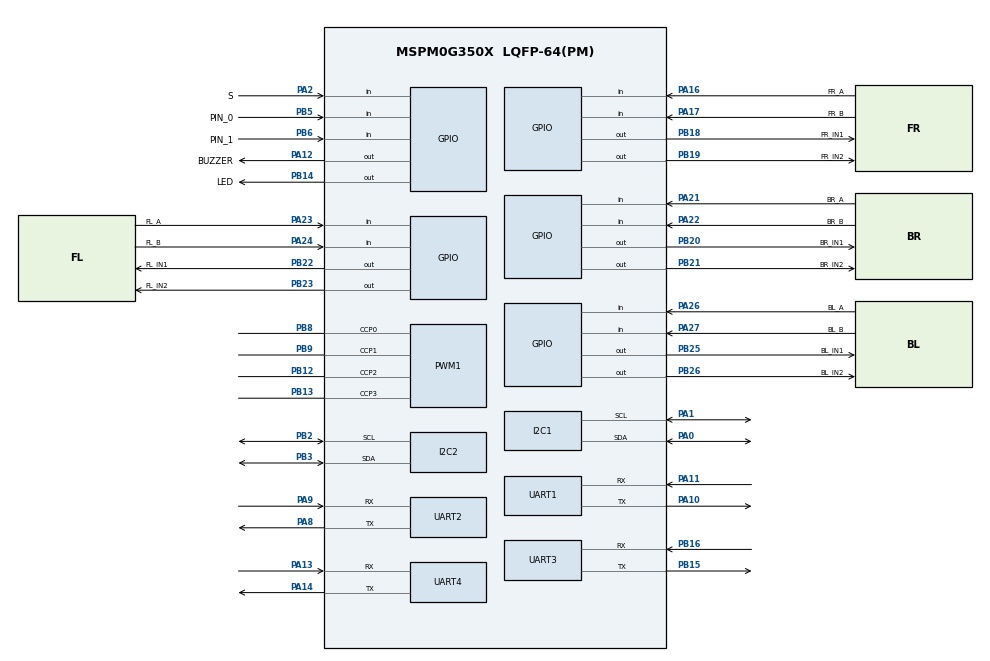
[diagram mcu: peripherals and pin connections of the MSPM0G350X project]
/**
 * @cliArgs --device "MSPM0G350X" --part "Default" --package "LQFP-64(PM)" --product "mspm0_sdk@2.05.01.01"
 * @versions {"tool":"1.24.0+4110"}
 */

/**
 * Import the modules used in this configuration.
 */
const GPIO   = scripting.addModule("/ti/driverlib/GPIO", {}, false);
const GPIO1  = GPIO.addInstance();
const GPIO2  = GPIO.addInstance();
const GPIO3  = GPIO.addInstance();
const GPIO4  = GPIO.addInstance();
const I2C    = scripting.addModule("/ti/driverlib/I2C", {}, false);
const I2C1   = I2C.addInstance();
const I2C2   = I2C.addInstance();
const PWM    = scripting.addModule("/ti/driverlib/PWM", {}, false);
const PWM1   = PWM.addInstance();
const SYSCTL = scripting.addModule("/ti/driverlib/SYSCTL");
const TIMER  = scripting.addModule("/ti/driverlib/TIMER", {}, false);
const TIMER1 = TIMER.addInstance();
const TIMER2 = TIMER.addInstance();
const UART   = scripting.addModule("/ti/driverlib/UART", {}, false);
const UART1  = UART.addInstance();
const UART2  = UART.addInstance();
const UART3  = UART.addInstance();
const UART4  = UART.addInstance();

/**
 * Write custom configuration values to the imported modules.
 */
const divider2       = system.clockTree["HFCLK4MFPCLKDIV"];
divider2.divideValue = 10;

const divider9       = system.clockTree["UDIV"];
divider9.divideValue = 2;

const gate7  = system.clockTree["MFCLKGATE"];
gate7.enable = true;

const gate8  = system.clockTree["MFPCLKGATE"];
gate8.enable = true;

const multiplier2         = system.clockTree["PLL_QDIV"];
multiplier2.multiplyValue = 5;

const mux2       = system.clockTree["CANCLKMUX"];
mux2.inputSelect = "CANCLKMUX_PLLCLK1_OUT";

const mux4       = system.clockTree["EXHFMUX"];
mux4.inputSelect = "EXHFMUX_XTAL";

const mux5       = system.clockTree["EXLFMUX"];
mux5.inputSelect = "EXLFMUX_XTAL";

const mux8       = system.clockTree["HSCLKMUX"];
mux8.inputSelect = "HSCLKMUX_SYSPLL0";

const pinFunction4     = system.clockTree["HFXT"];
pinFunction4.inputFreq = 40;

const pinFunction6     = system.clockTree["LFXT"];
pinFunction6.inputFreq = 32.768;

GPIO1.$name                         = "GPIO_MOTOR_DIR";
GPIO1.port                          = "PORTB";
GPIO1.associatedPins.create(8);
GPIO1.associatedPins[0].$name       = "FR_IN1";
GPIO1.associatedPins[0].pin.$assign = "PB18";
GPIO1.associatedPins[1].$name       = "FR_IN2";
GPIO1.associatedPins[1].pin.$assign = "PB19";
GPIO1.associatedPins[2].$name       = "BR_IN1";
GPIO1.associatedPins[2].pin.$assign = "PB20";
GPIO1.associatedPins[3].$name       = "BR_IN2";
GPIO1.associatedPins[3].pin.$assign = "PB21";
GPIO1.associatedPins[4].$name       = "FL_IN1";
GPIO1.associatedPins[4].pin.$assign = "PB22";
GPIO1.associatedPins[5].$name       = "FL_IN2";
GPIO1.associatedPins[5].pin.$assign = "PB23";
GPIO1.associatedPins[6].$name       = "BL_IN1";
GPIO1.associatedPins[6].pin.$assign = "PB25";
GPIO1.associatedPins[7].$name       = "BL_IN2";
GPIO1.associatedPins[7].pin.$assign = "PB26";

const Board = scripting.addModule("/ti/driverlib/Board", {}, false);

GPIO2.$name                               = "GPIO_MOTOR_ENC";
GPIO2.port                                = "PORTA";
GPIO2.associatedPins.create(8);
GPIO2.associatedPins[0].direction         = "INPUT";
GPIO2.associatedPins[0].interruptEn       = true;
GPIO2.associatedPins[0].interruptPriority = "1";
GPIO2.associatedPins[0].polarity          = "RISE";
GPIO2.associatedPins[0].$name             = "FR_A";
GPIO2.associatedPins[0].pin.$assign       = "PA16";
GPIO2.associatedPins[1].direction         = "INPUT";
GPIO2.associatedPins[1].interruptEn       = true;
GPIO2.associatedPins[1].interruptPriority = "1";
GPIO2.associatedPins[1].polarity          = "RISE";
GPIO2.associatedPins[1].$name             = "FR_B";
GPIO2.associatedPins[1].pin.$assign       = "PA17";
GPIO2.associatedPins[2].direction         = "INPUT";
GPIO2.associatedPins[2].interruptEn       = true;
GPIO2.associatedPins[2].interruptPriority = "1";
GPIO2.associatedPins[2].polarity          = "RISE";
GPIO2.associatedPins[2].$name             = "BR_A";
GPIO2.associatedPins[2].pin.$assign       = "PA21";
GPIO2.associatedPins[3].direction         = "INPUT";
GPIO2.associatedPins[3].interruptEn       = true;
GPIO2.associatedPins[3].interruptPriority = "1";
GPIO2.associatedPins[3].polarity          = "RISE";
GPIO2.associatedPins[3].$name             = "BR_B";
GPIO2.associatedPins[3].pin.$assign       = "PA22";
GPIO2.associatedPins[4].direction         = "INPUT";
GPIO2.associatedPins[4].interruptEn       = true;
GPIO2.associatedPins[4].interruptPriority = "1";
GPIO2.associatedPins[4].polarity          = "RISE";
GPIO2.associatedPins[4].$name             = "FL_A";
GPIO2.associatedPins[4].pin.$assign       = "PA23";
GPIO2.associatedPins[5].direction         = "INPUT";
GPIO2.associatedPins[5].polarity          = "RISE";
GPIO2.associatedPins[5].interruptEn       = true;
GPIO2.associatedPins[5].interruptPriority = "1";
GPIO2.associatedPins[5].$name             = "FL_B";
GPIO2.associatedPins[5].pin.$assign       = "PA24";
GPIO2.associatedPins[6].direction         = "INPUT";
GPIO2.associatedPins[6].interruptEn       = true;
GPIO2.associatedPins[6].interruptPriority = "1";
GPIO2.associatedPins[6].polarity          = "RISE";
GPIO2.associatedPins[6].$name             = "BL_A";
GPIO2.associatedPins[6].pin.$assign       = "PA26";
GPIO2.associatedPins[7].direction         = "INPUT";
GPIO2.associatedPins[7].polarity          = "RISE";
GPIO2.associatedPins[7].interruptEn       = true;
GPIO2.associatedPins[7].interruptPriority = "1";
GPIO2.associatedPins[7].$name             = "BL_B";
GPIO2.associatedPins[7].pin.$assign       = "PA27";

GPIO3.$name                         = "GPIO_PERIPH";
GPIO3.associatedPins.create(3);
GPIO3.associatedPins[0].$name       = "LED";
GPIO3.associatedPins[0].assignedPin = "14";
GPIO3.associatedPins[0].pin.$assign = "PB14";
GPIO3.associatedPins[1].$name       = "BUZZER";
GPIO3.associatedPins[1].pin.$assign = "PA12";
GPIO3.associatedPins[2].$name       = "S";
GPIO3.associatedPins[2].direction   = "INPUT";
GPIO3.associatedPins[2].pin.$assign = "PA2";

GPIO4.$name                         = "GPIO_IR";
GPIO4.associatedPins.create(2);
GPIO4.associatedPins[0].$name       = "PIN_0";
GPIO4.associatedPins[0].direction   = "INPUT";
GPIO4.associatedPins[0].pin.$assign = "PB5";
GPIO4.associatedPins[1].$name       = "PIN_1";
GPIO4.associatedPins[1].direction   = "INPUT";
GPIO4.associatedPins[1].pin.$assign = "PB6";

I2C1.$name                           = "I2C_0";
I2C1.basicEnableController           = true;
I2C1.basicControllerStandardBusSpeed = "Fast";
I2C1.peripheral.$assign              = "I2C0";
I2C1.peripheral.sdaPin.$assign       = "PA0";
I2C1.peripheral.sclPin.$assign       = "PA1";
I2C1.sdaPinConfig.$name              = "ti_driverlib_gpio_GPIOPinGeneric8";
I2C1.sclPinConfig.$name              = "ti_driverlib_gpio_GPIOPinGeneric9";

I2C2.$name                           = "I2C_1";
I2C2.basicEnableController           = true;
I2C2.basicControllerStandardBusSpeed = "Fast";
I2C2.peripheral.$assign              = "I2C1";
I2C2.peripheral.sdaPin.$assign       = "PB3";
I2C2.peripheral.sclPin.$assign       = "PB2";
I2C2.sdaPinConfig.$name              = "ti_driverlib_gpio_GPIOPinGeneric10";
I2C2.sclPinConfig.$name              = "ti_driverlib_gpio_GPIOPinGeneric11";

PWM1.clockDivider                       = 8;
PWM1.pwmMode                            = "EDGE_ALIGN_UP";
PWM1.ccIndex                            = [0,1,2,3];
PWM1.$name                              = "TIMA0_PWM";
PWM1.PWM_CHANNEL_0.$name                = "ti_driverlib_pwm_PWMTimerCC0";
PWM1.PWM_CHANNEL_1.$name                = "ti_driverlib_pwm_PWMTimerCC1";
PWM1.ccp0PinConfig.direction            = scripting.forceWrite("OUTPUT");
PWM1.ccp0PinConfig.hideOutputInversion  = scripting.forceWrite(false);
PWM1.ccp0PinConfig.onlyInternalResistor = scripting.forceWrite(false);
PWM1.ccp0PinConfig.passedPeripheralType = scripting.forceWrite("Digital");
PWM1.ccp0PinConfig.$name                = "ti_driverlib_gpio_GPIOPinGeneric12";
PWM1.ccp1PinConfig.direction            = scripting.forceWrite("OUTPUT");
PWM1.ccp1PinConfig.hideOutputInversion  = scripting.forceWrite(false);
PWM1.ccp1PinConfig.onlyInternalResistor = scripting.forceWrite(false);
PWM1.ccp1PinConfig.passedPeripheralType = scripting.forceWrite("Digital");
PWM1.ccp1PinConfig.$name                = "ti_driverlib_gpio_GPIOPinGeneric13";
PWM1.peripheral.$assign                 = "TIMA0";
PWM1.peripheral.ccp0Pin.$assign         = "PB8";
PWM1.peripheral.ccp1Pin.$assign         = "PB9";
PWM1.peripheral.ccp2Pin.$assign         = "PB12";
PWM1.peripheral.ccp3Pin.$assign         = "PB13";
PWM1.PWM_CHANNEL_2.$name                = "ti_driverlib_pwm_PWMTimerCC2";
PWM1.PWM_CHANNEL_3.$name                = "ti_driverlib_pwm_PWMTimerCC3";
PWM1.ccp2PinConfig.direction            = scripting.forceWrite("OUTPUT");
PWM1.ccp2PinConfig.hideOutputInversion  = scripting.forceWrite(false);
PWM1.ccp2PinConfig.onlyInternalResistor = scripting.forceWrite(false);
PWM1.ccp2PinConfig.passedPeripheralType = scripting.forceWrite("Digital");
PWM1.ccp2PinConfig.$name                = "ti_driverlib_gpio_GPIOPinGeneric14";
PWM1.ccp3PinConfig.direction            = scripting.forceWrite("OUTPUT");
PWM1.ccp3PinConfig.hideOutputInversion  = scripting.forceWrite(false);
PWM1.ccp3PinConfig.onlyInternalResistor = scripting.forceWrite(false);
PWM1.ccp3PinConfig.passedPeripheralType = scripting.forceWrite("Digital");
PWM1.ccp3PinConfig.$name                = "ti_driverlib_gpio_GPIOPinGeneric15";

SYSCTL.forceDefaultClkConfig = true;
SYSCTL.clockTreeEn           = true;
SYSCTL.MFPCLKSource          = "HFCLK";
SYSCTL.HFCLK4MFPCLKDIV       = "10";
scripting.suppress("For best practices when the CPUCLK is running at 32MHz and above, clear the flash status bit using DL_FlashCTL_executeClearStatus\\(\\) before executing any flash operation\\. Otherwise there may be false positives\\.", SYSCTL);

TIMER1.$name              = "TIMER_ENC";
TIMER1.timerClkDiv        = 8;
TIMER1.timerClkPrescale   = 10;
TIMER1.timerPeriod        = "0.02";
TIMER1.timerMode          = "PERIODIC";
TIMER1.interrupts         = ["ZERO"];
TIMER1.interruptPriority  = "2";
TIMER1.peripheral.$assign = "TIMG0";

TIMER2.$name              = "TIMER_General";
TIMER2.timerPeriod        = "0.025";
TIMER2.timerClkDiv        = 8;
TIMER2.timerClkPrescale   = 10;
TIMER2.interrupts         = ["ZERO"];
TIMER2.interruptPriority  = "1";
TIMER2.peripheral.$assign = "TIMG6";

UART1.targetBaudRate                   = 115200;
UART1.$name                            = "UART0_DEBUG";
UART1.peripheral.$assign               = "UART0";
UART1.peripheral.rxPin.$assign         = "PA11";
UART1.peripheral.txPin.$assign         = "PA10";
UART1.txPinConfig.direction            = scripting.forceWrite("OUTPUT");
UART1.txPinConfig.hideOutputInversion  = scripting.forceWrite(false);
UART1.txPinConfig.onlyInternalResistor = scripting.forceWrite(false);
UART1.txPinConfig.passedPeripheralType = scripting.forceWrite("Digital");
UART1.txPinConfig.$name                = "ti_driverlib_gpio_GPIOPinGeneric0";
UART1.rxPinConfig.hideOutputInversion  = scripting.forceWrite(false);
UART1.rxPinConfig.onlyInternalResistor = scripting.forceWrite(false);
UART1.rxPinConfig.passedPeripheralType = scripting.forceWrite("Digital");
UART1.rxPinConfig.$name                = "ti_driverlib_gpio_GPIOPinGeneric1";

UART2.targetBaudRate                   = 115200;
UART2.$name                            = "UART1_JY901S";
UART2.enabledInterrupts                = ["RX"];
UART2.interruptPriority                = "2";
UART2.peripheral.$assign               = "UART1";
UART2.peripheral.rxPin.$assign         = "PA9";
UART2.peripheral.txPin.$assign         = "PA8";
UART2.txPinConfig.direction            = scripting.forceWrite("OUTPUT");
UART2.txPinConfig.hideOutputInversion  = scripting.forceWrite(false);
UART2.txPinConfig.onlyInternalResistor = scripting.forceWrite(false);
UART2.txPinConfig.passedPeripheralType = scripting.forceWrite("Digital");
UART2.txPinConfig.$name                = "ti_driverlib_gpio_GPIOPinGeneric2";
UART2.rxPinConfig.hideOutputInversion  = scripting.forceWrite(false);
UART2.rxPinConfig.onlyInternalResistor = scripting.forceWrite(false);
UART2.rxPinConfig.passedPeripheralType = scripting.forceWrite("Digital");
UART2.rxPinConfig.$name                = "ti_driverlib_gpio_GPIOPinGeneric3";

UART3.$name                            = "UART2_LCD";
UART3.targetBaudRate                   = 115200;
UART3.peripheral.$assign               = "UART2";
UART3.peripheral.rxPin.$assign         = "PB16";
UART3.peripheral.txPin.$assign         = "PB15";
UART3.txPinConfig.direction            = scripting.forceWrite("OUTPUT");
UART3.txPinConfig.hideOutputInversion  = scripting.forceWrite(false);
UART3.txPinConfig.onlyInternalResistor = scripting.forceWrite(false);
UART3.txPinConfig.passedPeripheralType = scripting.forceWrite("Digital");
UART3.txPinConfig.$name                = "ti_driverlib_gpio_GPIOPinGeneric4";
UART3.rxPinConfig.hideOutputInversion  = scripting.forceWrite(false);
UART3.rxPinConfig.onlyInternalResistor = scripting.forceWrite(false);
UART3.rxPinConfig.passedPeripheralType = scripting.forceWrite("Digital");
UART3.rxPinConfig.$name                = "ti_driverlib_gpio_GPIOPinGeneric5";

UART4.$name                            = "UART3_K230";
UART4.targetBaudRate                   = 115200;
UART4.peripheral.$assign               = "UART3";
UART4.peripheral.rxPin.$assign         = "PA13";
UART4.peripheral.txPin.$assign         = "PA14";
UART4.txPinConfig.direction            = scripting.forceWrite("OUTPUT");
UART4.txPinConfig.hideOutputInversion  = scripting.forceWrite(false);
UART4.txPinConfig.onlyInternalResistor = scripting.forceWrite(false);
UART4.txPinConfig.passedPeripheralType = scripting.forceWrite("Digital");
UART4.txPinConfig.$name                = "ti_driverlib_gpio_GPIOPinGeneric6";
UART4.rxPinConfig.hideOutputInversion  = scripting.forceWrite(false);
UART4.rxPinConfig.onlyInternalResistor = scripting.forceWrite(false);
UART4.rxPinConfig.passedPeripheralType = scripting.forceWrite("Digital");
UART4.rxPinConfig.$name                = "ti_driverlib_gpio_GPIOPinGeneric7";

/**
 * Pinmux solution for unlocked pins/peripherals. This ensures that minor changes to the automatic solver in a future
 * version of the tool will not impact the pinmux you originally saw.  These lines can be completely deleted in order to
 * re-solve from scratch.
 */
Board.peripheral.$suggestSolution          = "DEBUGSS";
Board.peripheral.swclkPin.$suggestSolution = "PA20";
Board.peripheral.swdioPin.$suggestSolution = "PA19";
